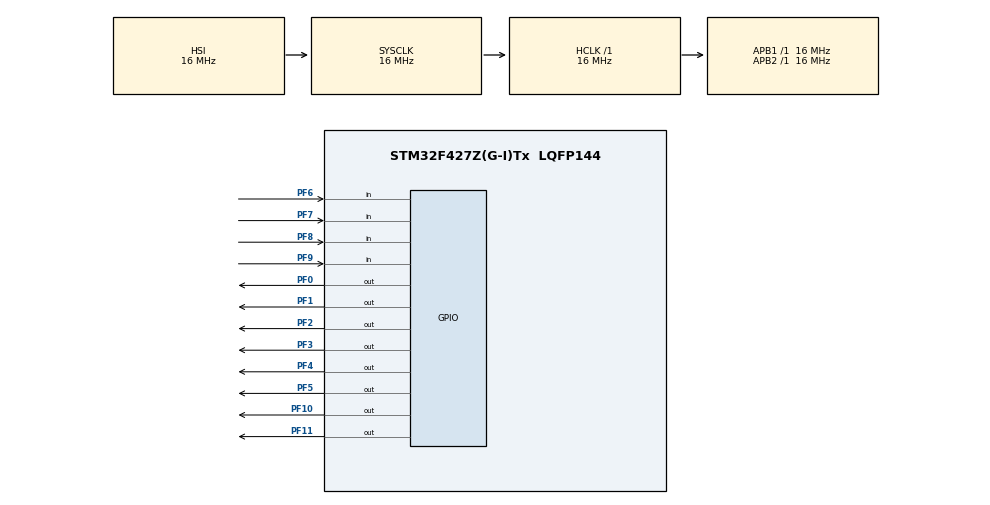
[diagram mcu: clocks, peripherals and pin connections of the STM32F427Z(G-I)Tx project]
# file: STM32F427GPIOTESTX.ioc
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FREERTOS.Tasks01=defaultTask,24,128,StartDefaultTask,Default,NULL,Dynamic,NULL,NULL
FREERTOS.configUSE_NEWLIB_REENTRANT=1
Mcu.Family=STM32F4
Mcu.Name=STM32F427Z(G-I)Tx
Mcu.Package=LQFP144
NVIC.PriorityGroup=NVIC_PRIORITYGROUP_4
NVIC.TIM1_UP_TIM10_IRQn=true\:15\:0\:false\:false\:true\:false\:false\:true\:true
NVIC.TimeBase=TIM1_UP_TIM10_IRQn
NVIC.TimeBaseIP=TIM1
PA13.Mode=JTAG_5_pins
PA13.Signal=SYS_JTMS-SWDIO
PA14.Mode=JTAG_5_pins
PA14.Signal=SYS_JTCK-SWCLK
PA15.Mode=JTAG_5_pins
PA15.Signal=SYS_JTDI
PB3.Mode=JTAG_5_pins
PB3.Signal=SYS_JTDO-SWO
PB4.Mode=JTAG_5_pins
PB4.Signal=SYS_JTRST
PC14/OSC32_IN.Mode=LSE-External-Oscillator
PC14/OSC32_IN.Signal=RCC_OSC32_IN
PC15/OSC32_OUT.Mode=LSE-External-Oscillator
PC15/OSC32_OUT.Signal=RCC_OSC32_OUT
PF0.Signal=GPIO_Output
PF1.Signal=GPIO_Output
PF10.Signal=GPIO_Output
PF11.Signal=GPIO_Output
PF2.Signal=GPIO_Output
PF3.Signal=GPIO_Output
PF4.Signal=GPIO_Output
PF5.Signal=GPIO_Output
PF6.Signal=GPIO_Input
PF7.Signal=GPIO_Input
PF8.Signal=GPIO_Input
PF9.Signal=GPIO_Input
PH0/OSC_IN.Mode=HSE-External-Oscillator
PH0/OSC_IN.Signal=RCC_OSC_IN
PH1/OSC_OUT.Mode=HSE-External-Oscillator
PH1/OSC_OUT.Signal=RCC_OSC_OUT
ProjectManager.HeapSize=0x200
ProjectManager.StackSize=0x400
ProjectManager.TargetToolchain=STM32CubeIDE
RCC.AHBFreq_Value=16000000
RCC.APB1Freq_Value=16000000
RCC.APB2Freq_Value=16000000
RCC.CortexFreq_Value=16000000
RCC.HSE_VALUE=25000000
RCC.HSI_VALUE=16000000
RCC.SYSCLKFreq_VALUE=16000000
RCC.VCOOutputFreq_Value=192000000
VP_FREERTOS_VS_CMSIS_V2.Mode=CMSIS_V2
VP_SYS_VS_tim1.Mode=TIM1
board=custom

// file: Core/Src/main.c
/* USER CODE BEGIN Header */
/**
  ******************************************************************************
  * @file           : main.c
  * @brief          : Main program body
  ******************************************************************************
  * @attention
  *
  * Copyright (c) 2023 STMicroelectronics.
  * All rights reserved.
  *
  * This software is licensed under terms that can be found in the LICENSE file
  * in the root directory of this software component.
  * If no LICENSE file comes with this software, it is provided AS-IS.
  *
  ******************************************************************************
  */
/* USER CODE END Header */
#include "main.h"
#include "cmsis_os.h"

/* Definitions for defaultTask */
osThreadId_t defaultTaskHandle;
const osThreadAttr_t defaultTask_attributes = {
  .name = "defaultTask",
  .stack_size = 128 * 4,
  .priority = (osPriority_t) osPriorityNormal,
};

void SystemClock_Config(void);
static void MX_GPIO_Init(void);
void StartDefaultTask(void *argument);

int main(void)
{

  /* MCU Configuration--------------------------------------------------------*/

  /* Reset of all peripherals, Initializes the Flash interface and the Systick. */
  HAL_Init();

  /* Configure the system clock */
  SystemClock_Config();

  /* Initialize all configured peripherals */
  MX_GPIO_Init();

  /* Init scheduler */
  osKernelInitialize();

  /* Create the thread(s) */
  /* creation of defaultTask */
  defaultTaskHandle = osThreadNew(StartDefaultTask, NULL, &defaultTask_attributes);

  /* Start scheduler */
  osKernelStart();

  /* We should never get here as control is now taken by the scheduler */
  /* Infinite loop */
  while (1)
  {

  }
}

void SystemClock_Config(void)
{
  RCC_OscInitTypeDef RCC_OscInitStruct = {0};
  RCC_ClkInitTypeDef RCC_ClkInitStruct = {0};

  /** Configure the main internal regulator output voltage
  */
  __HAL_RCC_PWR_CLK_ENABLE();
  __HAL_PWR_VOLTAGESCALING_CONFIG(PWR_REGULATOR_VOLTAGE_SCALE3);

  /** Initializes the RCC Oscillators according to the specified parameters
  * in the RCC_OscInitTypeDef structure.
  */
  RCC_OscInitStruct.OscillatorType = RCC_OSCILLATORTYPE_HSI;
  RCC_OscInitStruct.HSIState = RCC_HSI_ON;
  RCC_OscInitStruct.HSICalibrationValue = RCC_HSICALIBRATION_DEFAULT;
  RCC_OscInitStruct.PLL.PLLState = RCC_PLL_NONE;
  if (HAL_RCC_OscConfig(&RCC_OscInitStruct) != HAL_OK)
  {
    Error_Handler();
  }

  /** Initializes the CPU, AHB and APB buses clocks
  */
  RCC_ClkInitStruct.ClockType = RCC_CLOCKTYPE_HCLK|RCC_CLOCKTYPE_SYSCLK
                              |RCC_CLOCKTYPE_PCLK1|RCC_CLOCKTYPE_PCLK2;
  RCC_ClkInitStruct.SYSCLKSource = RCC_SYSCLKSOURCE_HSI;
  RCC_ClkInitStruct.AHBCLKDivider = RCC_SYSCLK_DIV1;
  RCC_ClkInitStruct.APB1CLKDivider = RCC_HCLK_DIV1;
  RCC_ClkInitStruct.APB2CLKDivider = RCC_HCLK_DIV1;

  if (HAL_RCC_ClockConfig(&RCC_ClkInitStruct, FLASH_LATENCY_0) != HAL_OK)
  {
    Error_Handler();
  }
}

static void MX_GPIO_Init(void)
{
  GPIO_InitTypeDef GPIO_InitStruct = {0};

  /* GPIO Ports Clock Enable */
  __HAL_RCC_GPIOC_CLK_ENABLE();
  __HAL_RCC_GPIOF_CLK_ENABLE();
  __HAL_RCC_GPIOH_CLK_ENABLE();
  __HAL_RCC_GPIOA_CLK_ENABLE();
  __HAL_RCC_GPIOB_CLK_ENABLE();

  /*Configure GPIO pin Output Level */
  HAL_GPIO_WritePin(GPIOF, GPIO_PIN_0|GPIO_PIN_1|GPIO_PIN_2|GPIO_PIN_3
                          |GPIO_PIN_4|GPIO_PIN_5|GPIO_PIN_10|GPIO_PIN_11, GPIO_PIN_RESET);

  /*Configure GPIO pins : PF0 PF1 PF2 PF3
                           PF4 PF5 PF10 PF11 */
  GPIO_InitStruct.Pin = GPIO_PIN_0|GPIO_PIN_1|GPIO_PIN_2|GPIO_PIN_3
                          |GPIO_PIN_4|GPIO_PIN_5|GPIO_PIN_10|GPIO_PIN_11;
  GPIO_InitStruct.Mode = GPIO_MODE_OUTPUT_PP;
  GPIO_InitStruct.Pull = GPIO_NOPULL;
  GPIO_InitStruct.Speed = GPIO_SPEED_FREQ_LOW;
  HAL_GPIO_Init(GPIOF, &GPIO_InitStruct);

  /*Configure GPIO pins : PF6 PF7 PF8 PF9 */
  GPIO_InitStruct.Pin = GPIO_PIN_6|GPIO_PIN_7|GPIO_PIN_8|GPIO_PIN_9;
  GPIO_InitStruct.Mode = GPIO_MODE_INPUT;
  GPIO_InitStruct.Pull = GPIO_NOPULL;
  HAL_GPIO_Init(GPIOF, &GPIO_InitStruct);

}

/* USER CODE BEGIN Header_StartDefaultTask */
/**
  * @brief  Function implementing the defaultTask thread.
  * @param  argument: Not used
  * @retval None
  */
/*
 * THE JOB TASK FROM HD DEPARTMENT -- FOR STM (STM32F427ZGT6):
 *
 * GPIOS:
 * PF0, PF1, PF2, PF3, PF4, PF5, PF10, PF11 - outputs;
 * PF6, PF7, PF8, PF9 – inputs.
 *
 * When PF6=1 then PF0=1, when PF6=0 then PF0=0;
 * When PF7=1 then PF1=1, when PF7=0 then PF1=0;
 * When PF8=1 then PF2=1, when PF8=0 then PF2=0;
 * When PF9=1 then PF3=1, when PF9=0 then PF3=0;
 *
 * When PF6=1 и PF7=1, then PF10=1, otherwise PF10=0;
 * When PF8=1 и PF9=1, then PF11=1, otherwise PF11=0;
 */
/* USER CODE END Header_StartDefaultTask */
void StartDefaultTask(void *argument)
{
  /* USER CODE BEGIN 5 */
  /* Infinite loop */
  for(;;)
  {
	/* A BABY TALK */

	// Read the inputs
	GPIO_PinState gf6 = HAL_GPIO_ReadPin(GPIOF, GPIO_PIN_6);
	GPIO_PinState gf7 = HAL_GPIO_ReadPin(GPIOF, GPIO_PIN_7);
	GPIO_PinState gf8 = HAL_GPIO_ReadPin(GPIOF, GPIO_PIN_8);
	GPIO_PinState gf9 = HAL_GPIO_ReadPin(GPIOF, GPIO_PIN_9);

	// GPIO_PinState has 0 or 1 integer value, so then can be used bitwise and
	// it is less portable but good enough for test
	GPIO_PinState gf10 = (int)gf6 & (int)gf7;
	GPIO_PinState gf11 = (int)gf8 & (int)gf9;

	// Write the outputs
	HAL_GPIO_WritePin(GPIOF, GPIO_PIN_0, gf6);
	HAL_GPIO_WritePin(GPIOF, GPIO_PIN_1, gf7);
	HAL_GPIO_WritePin(GPIOF, GPIO_PIN_2, gf8);
	HAL_GPIO_WritePin(GPIOF, GPIO_PIN_3, gf9);
	HAL_GPIO_WritePin(GPIOF, GPIO_PIN_10, gf10);
	HAL_GPIO_WritePin(GPIOF, GPIO_PIN_11, gf11);

    osDelay(10);
  }
  /* USER CODE END 5 */
}

void HAL_TIM_PeriodElapsedCallback(TIM_HandleTypeDef *htim)
{
  if (htim->Instance == TIM1) {
    HAL_IncTick();
  }
}

void Error_Handler(void)
{
  __disable_irq();
  while (1)
  {
  }
}
